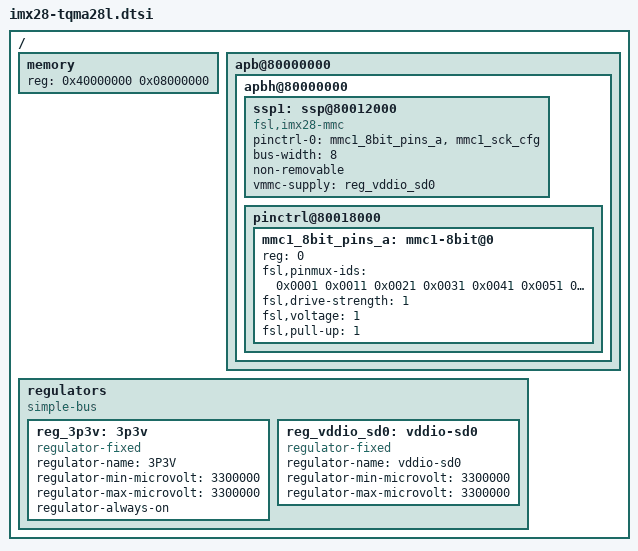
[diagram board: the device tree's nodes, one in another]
/*
 * Copyright 2012 Freescale Semiconductor, Inc.
 *
 * The code contained herein is licensed under the GNU General Public
 * License. You may obtain a copy of the GNU General Public License
 * Version 2 or later at the following locations:
 *
 * http://www.opensource.org/licenses/gpl-license.html
 * http://www.gnu.org/copyleft/gpl.html
 */

/include/ "imx28.dtsi"

/ {
	memory {
		reg = <0x40000000 0x08000000>;
	};

	apb@80000000 {
		apbh@80000000 {
			/* Attention: TQMa28L has e-MMC on SSP1 */
			ssp1: ssp@80012000 {
				compatible = "fsl,imx28-mmc";
				pinctrl-names = "default";
				pinctrl-0 = <&mmc1_8bit_pins_a
						&mmc1_sck_cfg>;
				bus-width = <8>;
				non-removable;
				vmmc-supply = <&reg_vddio_sd0>;
				status = "okay";
			};

			pinctrl@80018000 {
				mmc1_8bit_pins_a: mmc1-8bit@0 {
					reg = <0>;
					fsl,pinmux-ids = <
						0x0001 /* MX28_PAD_GPMI_D00__SSP1_D0 */
						0x0011 /* MX28_PAD_GPMI_D01__SSP1_D1 */
						0x0021 /* MX28_PAD_GPMI_D02__SSP1_D2 */
						0x0031 /* MX28_PAD_GPMI_D03__SSP1_D3 */
						0x0041 /* MX28_PAD_GPMI_D04__SSP1_D4 */
						0x0051 /* MX28_PAD_GPMI_D05__SSP1_D5 */
						0x0061 /* MX28_PAD_GPMI_D06__SSP1_D6 */
						0x0071 /* MX28_PAD_GPMI_D07__SSP1_D7 */
						0x0151 /* MX28_PAD_GPMI_RDY1__SSP1_CMD */
					>;
					fsl,drive-strength = <1>;
					fsl,voltage = <1>;
					fsl,pull-up = <1>;
				};
			};
		};
	};

	regulators {
		compatible = "simple-bus";

		reg_3p3v: 3p3v {
			compatible = "regulator-fixed";
			regulator-name = "3P3V";
			regulator-min-microvolt = <3300000>;
			regulator-max-microvolt = <3300000>;
			regulator-always-on;
		};

		reg_vddio_sd0: vddio-sd0 {
			compatible = "regulator-fixed";
			regulator-name = "vddio-sd0";
			regulator-min-microvolt = <3300000>;
			regulator-max-microvolt = <3300000>;
		};
	};
};
